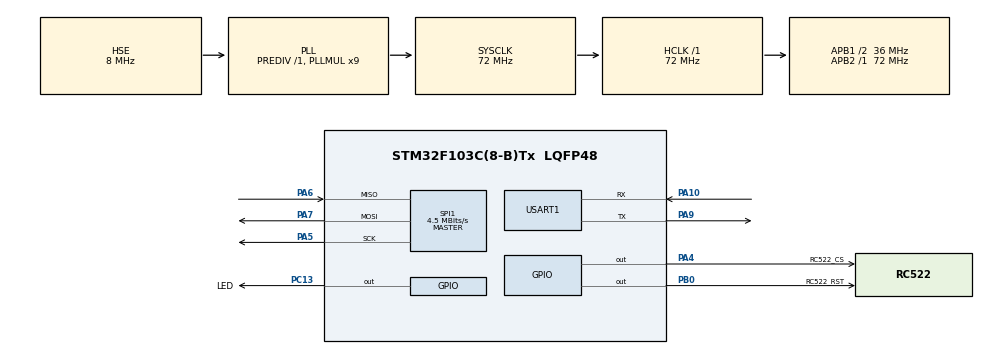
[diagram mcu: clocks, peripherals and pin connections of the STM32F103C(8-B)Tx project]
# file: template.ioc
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Mcu.Family=STM32F1
RCC.PLLSourceVirtual=RCC_PLLSOURCE_HSE
PC15-OSC32_OUT.Mode=LSE-External-Oscillator
PA6.Mode=Full_Duplex_Master
PA7.Mode=Full_Duplex_Master
PD1-OSC_OUT.Mode=HSE-External-Oscillator
PA10.Mode=Asynchronous
SPI1.VirtualType=VM_MASTER
PC13-TAMPER-RTC.Signal=GPIO_Output
PB0.GPIO_Label=RC522_RST
PD0-OSC_IN.Signal=RCC_OSC_IN
RCC.APB1CLKDivider=RCC_HCLK_DIV2
PC14-OSC32_IN.Signal=RCC_OSC32_IN
RCC.SYSCLKSource=RCC_SYSCLKSOURCE_PLLCLK
ProjectManager.StackSize=0x400
PD1-OSC_OUT.Signal=RCC_OSC_OUT
PB0.GPIO_Speed=GPIO_SPEED_FREQ_LOW
PA13.Signal=SYS_JTMS-SWDIO
PA9.Mode=Asynchronous
ProjectManager.TargetToolchain=Makefile
SPI1.Direction=SPI_DIRECTION_2LINES
RCC.HCLKFreq_Value=72000000
RCC.APB2TimFreq_Value=72000000
PA9.Signal=USART1_TX
SPI1.CalculateBaudRate=4.5 MBits/s
RCC.USBFreq_Value=72000000
PC15-OSC32_OUT.Signal=RCC_OSC32_OUT
RCC.AHBFreq_Value=72000000
PD0-OSC_IN.Mode=HSE-External-Oscillator
PA5.Signal=SPI1_SCK
board=custom
PC13-TAMPER-RTC.GPIO_Label=LED
RCC.PLLMUL=RCC_PLL_MUL9
RCC.APB2Freq_Value=72000000
SPI1.CRCCalculation=SPI_CRCCALCULATION_DISABLE
PC14-OSC32_IN.Mode=LSE-External-Oscillator
PC13-TAMPER-RTC.PinState=GPIO_PIN_SET
SPI1.Mode=SPI_MODE_MASTER
PA14.Mode=Serial_Wire
PA13.Mode=Serial_Wire
Mcu.Name=STM32F103C(8-B)Tx
PA4.Signal=GPIO_Output
RCC.SYSCLKFreq_VALUE=72000000
Mcu.Package=LQFP48
PA6.Signal=SPI1_MISO
USART1.VirtualMode=VM_ASYNC
PA10.Signal=USART1_RX
PA14.Signal=SYS_JTCK-SWCLK
ProjectManager.HeapSize=0x200
NVIC.PriorityGroup=NVIC_PRIORITYGROUP_4
RCC.APB1TimFreq_Value=72000000
RCC.APB1Freq_Value=36000000
SPI1.BaudRatePrescaler=SPI_BAUDRATEPRESCALER_16
PB0.Signal=GPIO_Output
PA4.GPIO_Label=RC522_CS
PA5.Mode=Full_Duplex_Master
PA7.Signal=SPI1_MOSI

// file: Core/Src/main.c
/* USER CODE BEGIN Header */
/**
  ******************************************************************************
  * @file           : main.c
  * @brief          : Main program body
  ******************************************************************************
  * @attention
  *
  * <h2><center>&copy; Copyright (c) 2021 STMicroelectronics.
  * All rights reserved.</center></h2>
  *
  * This software component is licensed by ST under BSD 3-Clause license,
  * the "License"; You may not use this file except in compliance with the
  * License. You may obtain a copy of the License at:
  *                        opensource.org/licenses/BSD-3-Clause
  *
  ******************************************************************************
  */
/* USER CODE END Header */
#include "main.h"
#include "spi.h"
#include "usart.h"
#include "gpio.h"

/* USER CODE BEGIN Includes */
#include "RC522.h"
#include <stdio.h>
/* USER CODE END Includes */

void SystemClock_Config(void);

int main(void)
{

  /* MCU Configuration--------------------------------------------------------*/

  /* Reset of all peripherals, Initializes the Flash interface and the Systick. */
  HAL_Init();

  /* Configure the system clock */
  SystemClock_Config();

  /* Initialize all configured peripherals */
  MX_GPIO_Init();
  MX_USART1_UART_Init();
  MX_SPI1_Init();
  /* USER CODE BEGIN 2 */
  RC522_Init();
  /* USER CODE END 2 */

  /* Infinite loop */
  /* USER CODE BEGIN WHILE */
  while (1)
  {
    RC522_Handle1();

    /* USER CODE END WHILE */

  }
}

void SystemClock_Config(void)
{
  RCC_OscInitTypeDef RCC_OscInitStruct = {0};
  RCC_ClkInitTypeDef RCC_ClkInitStruct = {0};

  /** Initializes the RCC Oscillators according to the specified parameters
  * in the RCC_OscInitTypeDef structure.
  */
  RCC_OscInitStruct.OscillatorType = RCC_OSCILLATORTYPE_HSE;
  RCC_OscInitStruct.HSEState = RCC_HSE_ON;
  RCC_OscInitStruct.HSEPredivValue = RCC_HSE_PREDIV_DIV1;
  RCC_OscInitStruct.HSIState = RCC_HSI_ON;
  RCC_OscInitStruct.PLL.PLLState = RCC_PLL_ON;
  RCC_OscInitStruct.PLL.PLLSource = RCC_PLLSOURCE_HSE;
  RCC_OscInitStruct.PLL.PLLMUL = RCC_PLL_MUL9;
  if (HAL_RCC_OscConfig(&RCC_OscInitStruct) != HAL_OK)
  {
    Error_Handler();
  }
  /** Initializes the CPU, AHB and APB buses clocks
  */
  RCC_ClkInitStruct.ClockType = RCC_CLOCKTYPE_HCLK|RCC_CLOCKTYPE_SYSCLK
                              |RCC_CLOCKTYPE_PCLK1|RCC_CLOCKTYPE_PCLK2;
  RCC_ClkInitStruct.SYSCLKSource = RCC_SYSCLKSOURCE_PLLCLK;
  RCC_ClkInitStruct.AHBCLKDivider = RCC_SYSCLK_DIV1;
  RCC_ClkInitStruct.APB1CLKDivider = RCC_HCLK_DIV2;
  RCC_ClkInitStruct.APB2CLKDivider = RCC_HCLK_DIV1;

  if (HAL_RCC_ClockConfig(&RCC_ClkInitStruct, FLASH_LATENCY_2) != HAL_OK)
  {
    Error_Handler();
  }
}

void Error_Handler(void)
{
  __disable_irq();
  while (1)
  {
  }
}

/************************ (C) COPYRIGHT STMicroelectronics *****END OF FILE****/
